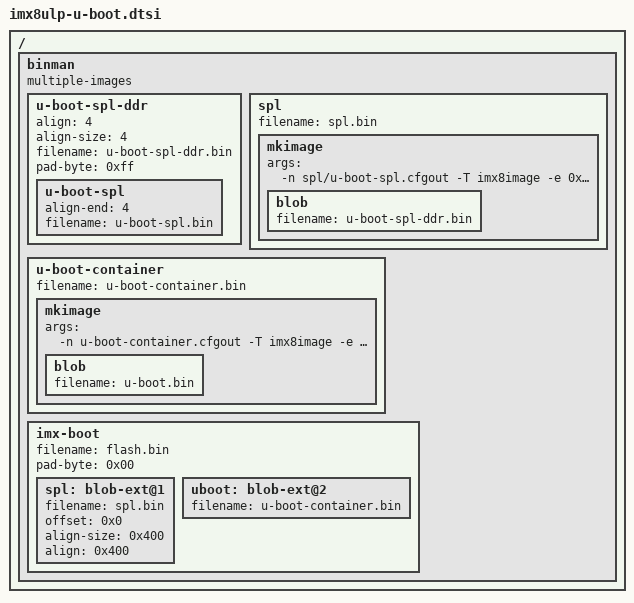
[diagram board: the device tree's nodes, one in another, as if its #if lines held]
// SPDX-License-Identifier: GPL-2.0+

#ifdef CONFIG_BINMAN
/ {
	binman: binman {
		multiple-images;
	};
};

&binman {
	u-boot-spl-ddr {
		align = <4>;
		align-size = <4>;
		filename = "u-boot-spl-ddr.bin";
		pad-byte = <0xff>;

		u-boot-spl {
			align-end = <4>;
			filename = "u-boot-spl.bin";
		};
	};

	spl {
		filename = "spl.bin";

		mkimage {
			args = "-n spl/u-boot-spl.cfgout -T imx8image -e 0x22020000";

			blob {
				filename = "u-boot-spl-ddr.bin";
			};
		};
	};

	u-boot-container {
		filename = "u-boot-container.bin";

		mkimage {
			args = "-n u-boot-container.cfgout -T imx8image -e 0x0";

			blob {
				filename = "u-boot.bin";
			};
		};
	};

	imx-boot {
		filename = "flash.bin";
		pad-byte = <0x00>;

		spl: blob-ext@1 {
			filename = "spl.bin";
			offset = <0x0>;
			align-size = <0x400>;
			align = <0x400>;
		};

		uboot: blob-ext@2 {
			filename = "u-boot-container.bin";
		};
	};
};
#endif
